# PIC32CK2051SG00144 register map
Vendor: Microchip Technology; Series: PIC32CKSG00; File version: 0
CPU: CM33 r0p0, little endian, MPU, FPU, DSP, 3 interrupt priority bits, 158 interrupts, 23 SAU regions
Registers are 32-bit, read-write, reset 0x0 unless marked. A register's access mark holds for its fields unless they carry their own. Offsets are from the block's base; [hi:lo] are bit positions; {n}, {i} and the like mark numbered series; 'fields as' and 'values as' point back to an identical list.

## FCW — Flash Write Control (FCW)
Base 0x44004000
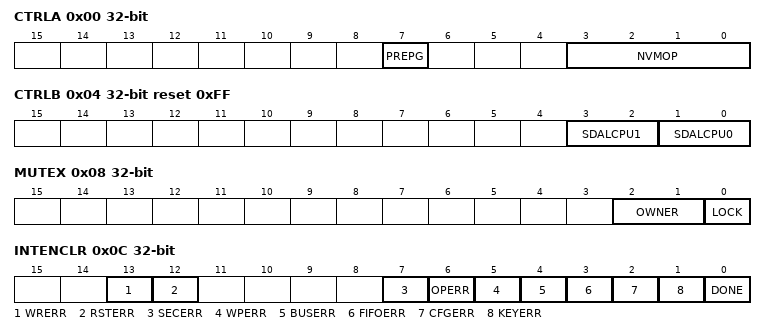
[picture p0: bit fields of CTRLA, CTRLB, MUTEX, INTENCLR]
0x00 CTRLA — NVM Write Control Register
  [7] PREPG — NVM Pre-Program Configuration Bit
  [3:0] NVMOP — NVM Operation
0x04 CTRLB reset 0xFF — NVM Control B Register
  [3:2] SDALCPU1 — Set DAL for CPU n
  [1:0] SDALCPU0 — Set DAL for CPU n
0x08 MUTEX — NVM MUTEX Register
  [2:1] OWNER — Flash Write Controller (FCW) Owner ID
  [0] LOCK — Flash Write Controller (FCW) Lock by Owner
0x0C INTENCLR write-1-clears — NVM Interrupt Enable Clear Register
  [13] WRERR — Write Error Interrupt Enable Bit
  [12] RSTERR — Reset or Brown Out Detect Error Interrupt Enable Bit
  [7] SECERR — Security Violation Error Interrupt Enable Bit
  [6] OPERR — NVMOP Error Interrupt Enable Bit
  [5] WPERR — Write Protection Error Interrupt Enable Bit
  [4] BUSERR — AHB Bus Error during Row Write Interrupt Enable Bit
  [3] FIFOERR — FIFO Underrun during Row Write Interrupt Enable Bit
  [2] CFGERR — Configuration Error Interrupt Enable Bit
  [1] KEYERR — Key Error Interrupt Enable Bit
  [0] DONE — NVM Operation Done Interrupt Enable Bit
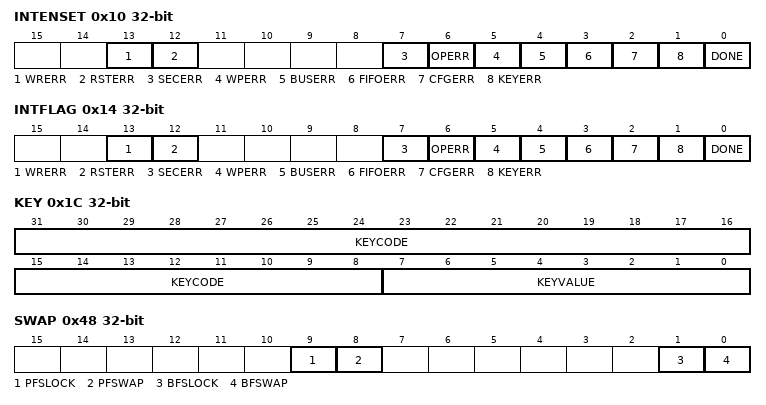
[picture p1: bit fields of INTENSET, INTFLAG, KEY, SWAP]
0x10 INTENSET write-1-sets — NVM Interrupt Enable SET Register
  fields as INTENCLR
0x14 INTFLAG write-1-clears — NVM Interrupt Flag Register
  [13] WRERR — Write Error Flag Bit
  [12] RSTERR — Reset or Brown Out Detect Error Flag Bit
  [7] SECERR — Security Violation Error Bit
  [6] OPERR — NVMOP Error Flag Bit
  [5] WPERR — Write Protection Error Flag Bit
  [4] BUSERR — AHB Bus Error during Row Write Flag Bit
  [3] FIFOERR — FIFO Underrun during Row Write Flag Bit
  [2] CFGERR — Configuration Error Flag Bit
  [1] KEYERR — Key Error Flag Bit
  [0] DONE — NVM Operation Done Flag Bit
0x18 STATUS — NVM Status Register
  [0] BUSY — NVM Busy Status
0x1C KEY — SFR Unlock Register
  [31:8] KEYCODE — NVM SFR Key Code
  [7:0] KEYVALUE — NVM SFR Key Value
0x20 ADDR — Flash Address Register
  [31:2] ADDR — Flash Address used by NVMOP
0x24 SRCADDR — Source Data Address Register
  [31:2] SRCADDR — Source Data (Word) Address
{0x28+4i} DATA[{i}] (i=0..7) — Flash Write Data Register
  [31:0] DATA — Flash Write Data
0x48 SWAP — NVM Panel Swap Register
  [9] PFSLOCK — PFM Swap Lock Bit
  [8] PFSWAP — PFM Swap Status/Control Bit
  [1] BFSLOCK — BFM Swap Lock Bit
  [0] BFSWAP — BFM Swap Status/Control Bit
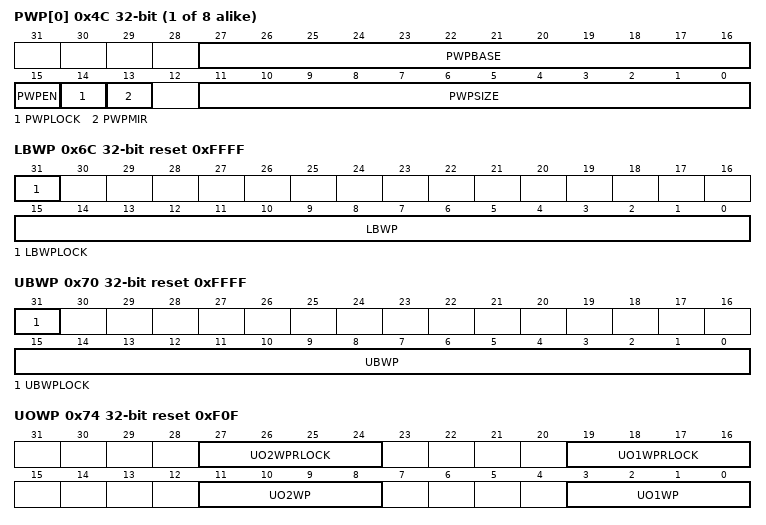
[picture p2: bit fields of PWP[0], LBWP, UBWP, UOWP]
{0x4C+4i} PWP[{i}] (i=0..7) — PFM Write Protect Region 0
  [27:16] PWPBASE — PWP Region 0 Base Address - 4KB Page Aligned
  [15] PWPEN — PWP Region 0 Enable Bit
  [14] PWPLOCK — PWP Region 0 Lock Bit
  [13] PWPMIR — Mirror PWP 0 bit
  [11:0] PWPSIZE — PWP Region 0 Size in 4KB pages
0x6C LBWP reset 0xFFFF — Lower BFM Write Protect Register
  [31] LBWPLOCK — LBWP Lock Bit
  [15:0] LBWP — Lower Boot Pages Write Protect Bits
0x70 UBWP reset 0xFFFF — Upper BFM Write Protect Register
  [31] UBWPLOCK — UBWP Register Lock Bit
  [15:0] UBWP — Upper Boot Pages Write Protect Bits
0x74 UOWP reset 0xF0F — User OTP Write Protect Register
  [27:24] UO2WPRLOCK — User OTP Page 2 WP Row Lock Bit
  [19:16] UO1WPRLOCK — User OTP Page 1 WP Row Lock Bit
  [11:8] UO2WP — User OTP Page 2 Write Protect Row Bit
  [3:0] UO1WP — User OTP Page 1 Write Protect Row Bit
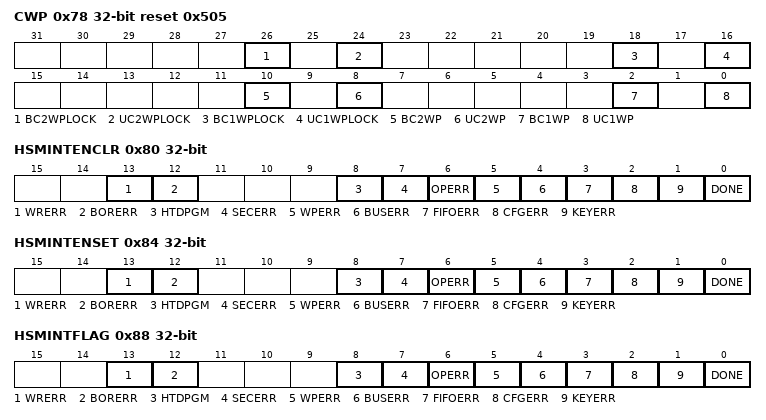
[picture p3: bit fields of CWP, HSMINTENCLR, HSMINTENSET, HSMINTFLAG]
0x78 CWP reset 0x505 — CFM Page Write Protect Register
  [26] BC2WPLOCK — Boot Configuration Page 2 WP Lock Bit
  [24] UC2WPLOCK — User Configuration Page 2 WP Lock Bit
  [18] BC1WPLOCK — Boot Configuration Page 1 WP Lock Bit
  [16] UC1WPLOCK — User Configuration Page 1 WP Lock Bit
  [10] BC2WP — Boot Configuration Page 2 Write Protect Bit
  [8] UC2WP — User Configuration Page 2 Write Protect Bit
  [2] BC1WP — Boot Configuration Page 1 Write Protect Bit
  [0] UC1WP — User Configuration Page 1 Write Protect Bit
0x80 HSMINTENCLR write-1-clears — HSM NVM Interrupt Enable Clear Register
  [13] WRERR — Write Error Interrupt Enable Bit
  [12] BORERR — Brown Out Detect Error Interrupt Enable Bit
  [8] HTDPGM — High Temperature Detect Error Interrupt Enable Bit
  [7] SECERR — Security Violation Error Interrupt Enable Bit
  [6] OPERR — NVMOP Error Interrupt Enable Bit
  [5] WPERR — Write Protection Error Interrupt Enable Bit
  [4] BUSERR — AHB Bus Error during Row Write Interrupt Enable Bit
  [3] FIFOERR — FIFO Underrun during Row Write Interrupt Enable Bit
  [2] CFGERR — Configuration Error Interrupt Enable Bit
  [1] KEYERR — Key Error Interrupt Enable Bit
  [0] DONE — NVM Operation Done Interrupt Enable Bit
0x84 HSMINTENSET write-1-sets — HSM NVM Interrupt Enable SET Register
  fields as HSMINTENCLR
0x88 HSMINTFLAG write-1-clears — HSM NVM Interrupt Flag Register
  [13] WRERR — Write Error Flag Bit
  [12] BORERR — Brown Out Detect Error Flag Bit
  [8] HTDPGM — High Temperature Detect Error Flag Bit
  [7] SECERR — Security Violation Error Bit
  [6] OPERR — NVMOP Error Flag Bit
  [5] WPERR — Write Protection Error Flag Bit
  [4] BUSERR — AHB Bus Error during Row Write Flag Bit
  [3] FIFOERR — FIFO Underrun during Row Write Flag Bit
  [2] CFGERR — Configuration Error Flag Bit
  [1] KEYERR — Key Error Flag Bit
  [0] DONE — NVM Operation Done Flag Bit
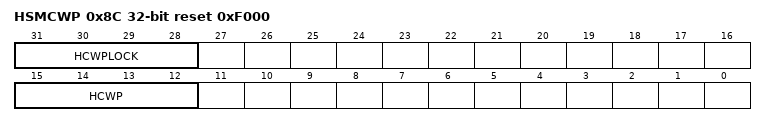
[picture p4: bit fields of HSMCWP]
0x8C HSMCWP reset 0xF000 — HSM CFG Write Protect Register
  [31:28] HCWPLOCK — HSMCWP Register Lock Bit
  [15:12] HCWP — HSM CFG Page Write Protect Bits
{0x90+4i} HSMLDAT[{i}] (i=0..7) reset 0xFFFFFFFF — HSM Tamper Lower Overwrite Data Register
{0xB0+4i} HSMUDAT[{i}] (i=0..7) reset 0xFFFFFFFF — HSM Tamper Upper Overwrite Data Register

## Notices in the file
Copyright (c) 2026 Microchip Technology Inc.
SPDX-License-Identifier: Apache-2.0
Licensed under the Apache License, Version 2.0 (the "License");
you may not use this file except in compliance with the License.
You may obtain a copy of the License at
http://www.apache.org/licenses/LICENSE-2.0
Unless required by applicable law or agreed to in writing, software
distributed under the License is distributed on an "AS IS" BASIS,
WITHOUT WARRANTIES OR CONDITIONS OF ANY KIND, either express or implied.
See the License for the specific language governing permissions and
limitations under the License.
